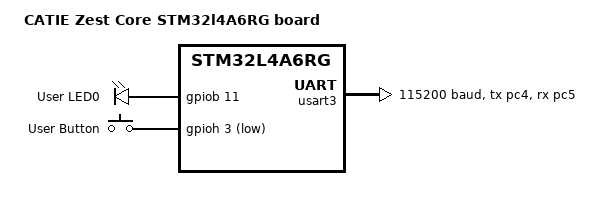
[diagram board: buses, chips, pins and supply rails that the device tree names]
/*
 * Copyright (c) 2023
 *
 * SPDX-License-Identifier: Apache-2.0
 */

/dts-v1/;
#include <st/l4/stm32l4a6Xg.dtsi>
#include <st/l4/stm32l4a6rgtx-pinctrl.dtsi>

/ {
	model = "CATIE Zest Core STM32l4A6RG board";
	compatible = "catie,zest-core-stm32l4a6rg";

	chosen {
		zephyr,console = &usart3;
		zephyr,shell-uart = &usart3;
		zephyr,sram = &sram0;
		zephyr,flash = &flash0;
	};

	leds {
		compatible = "gpio-leds";
		led_0: led_0 {
			gpios = <&gpiob 11 GPIO_ACTIVE_HIGH>;
			label = "User LED0";
		};
	};

	gpio_keys {
		compatible = "gpio-keys";
		user_button: button {
			label = "User Button";
			gpios = <&gpioh 3 GPIO_ACTIVE_LOW>;
		};
	};

	aliases {
		led0 = &led_0;
		sw0 = &user_button;
	};
};

&clk_msi {
	status = "okay";
};

&pll {
	div-m = <1>;
	mul-n = <40>;
	div-p = <7>;
	div-q = <2>;
	div-r = <2>;
	clocks = <&clk_msi>;
	status = "okay";
};

&rcc {
	clocks = <&pll>;
	clock-frequency = <DT_FREQ_M(80)>;
	ahb-prescaler = <1>;
	apb1-prescaler = <1>;
	apb2-prescaler = <1>;
};

&usart3 {
	pinctrl-0 = <&usart3_tx_pc4 &usart3_rx_pc5>;
	pinctrl-names = "default";
	current-speed = <115200>;
	status = "okay";
};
